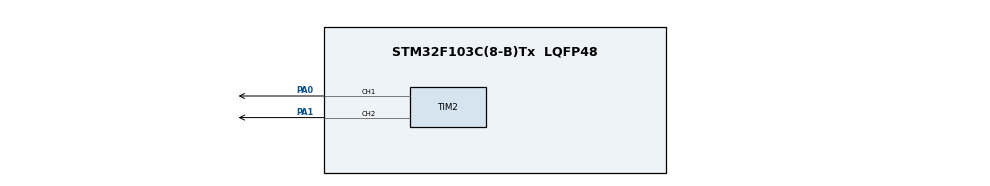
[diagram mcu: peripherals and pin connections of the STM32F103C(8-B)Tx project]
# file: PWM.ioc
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Mcu.Family=STM32F1
Mcu.Name=STM32F103C(8-B)Tx
Mcu.Package=LQFP48
NVIC.PriorityGroup=NVIC_PRIORITYGROUP_4
PA0-WKUP.Signal=S_TIM2_CH1_ETR
PA1.Signal=S_TIM2_CH2
PA13.Mode=Serial_Wire
PA13.Signal=SYS_JTMS-SWDIO
PA14.Mode=Serial_Wire
PA14.Signal=SYS_JTCK-SWCLK
PD0-OSC_IN.Mode=HSE-External-Oscillator
PD0-OSC_IN.Signal=RCC_OSC_IN
PD1-OSC_OUT.Mode=HSE-External-Oscillator
PD1-OSC_OUT.Signal=RCC_OSC_OUT
ProjectManager.HeapSize=0x200
ProjectManager.StackSize=0x400
ProjectManager.TargetToolchain=STM32CubeIDE
RCC.APB1Freq_Value=8000000
RCC.APB2Freq_Value=8000000
SH.S_TIM2_CH1_ETR.0=TIM2_CH1,PWM Generation1 CH1
SH.S_TIM2_CH2.0=TIM2_CH2,PWM Generation2 CH2
TIM2.Channel-PWM\ Generation1\ CH1=TIM_CHANNEL_1
TIM2.Channel-PWM\ Generation2\ CH2=TIM_CHANNEL_2
VP_TIM2_VS_ClockSourceINT.Mode=Internal
board=custom

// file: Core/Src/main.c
/* USER CODE BEGIN Header */
/**
  ******************************************************************************
  * @file           : main.c
  * @brief          : Main program body
  ******************************************************************************
  * @attention
  *
  * This software is licensed under terms that can be found in the LICENSE file
  * in the root directory of this software component.
  *
  ******************************************************************************
  */
/* USER CODE END Header */
#include "main.h"

/* USER CODE BEGIN PD */
#define MAX_DUTY_CYCLE 1000
#define STEP_DUTY_CYCLE 50
#define DELAY_MS 10
/* USER CODE END PD */

TIM_HandleTypeDef htim2;

void SystemClock_Config(void);
static void MX_GPIO_Init(void);
static void MX_TIM2_Init(void);
/* USER CODE BEGIN PFP */
void Set_PWM_DutyCycle(TIM_HandleTypeDef *htim, uint32_t Channel, uint16_t duty_cycle);
/* USER CODE END PFP */

/* USER CODE BEGIN 0 */
void Set_PWM_DutyCycle(TIM_HandleTypeDef *htim, uint32_t Channel, uint16_t duty_cycle) {
    if (duty_cycle <= MAX_DUTY_CYCLE) {
        __HAL_TIM_SET_COMPARE(htim, Channel, duty_cycle);
    }
}

void PWM_Mode() {
    HAL_TIM_PWM_Start(&htim2, TIM_CHANNEL_1);
    HAL_TIM_PWM_Start(&htim2, TIM_CHANNEL_2);

    // Tăng độ rộng xung trên cả hai kênh
    for (uint16_t duty_cycle = 0; duty_cycle <= MAX_DUTY_CYCLE; duty_cycle += STEP_DUTY_CYCLE) {
        Set_PWM_DutyCycle(&htim2, TIM_CHANNEL_1, duty_cycle);
        Set_PWM_DutyCycle(&htim2, TIM_CHANNEL_2, duty_cycle);
        HAL_Delay(DELAY_MS);
    }

    // Giảm độ rộng xung trên cả hai kênh
    for (uint16_t duty_cycle = MAX_DUTY_CYCLE; duty_cycle > 0; duty_cycle -= STEP_DUTY_CYCLE) {
        Set_PWM_DutyCycle(&htim2, TIM_CHANNEL_1, duty_cycle);
        Set_PWM_DutyCycle(&htim2, TIM_CHANNEL_2, duty_cycle);
        HAL_Delay(DELAY_MS);
    }

    HAL_TIM_PWM_Stop(&htim2, TIM_CHANNEL_1);
    HAL_TIM_PWM_Stop(&htim2, TIM_CHANNEL_2);
}
/* USER CODE END 0 */

int main(void)
{

  /* MCU Configuration--------------------------------------------------------*/

  /* Reset of all peripherals, Initializes the Flash interface and the Systick. */
  HAL_Init();

  /* Configure the system clock */
  SystemClock_Config();

  /* Initialize all configured peripherals */
  MX_GPIO_Init();
  MX_TIM2_Init();

  /* Infinite loop */
  /* USER CODE BEGIN WHILE */
  while (1) {
      PWM_Mode();
  }
  /* USER CODE END WHILE */
}

void SystemClock_Config(void)
{
  RCC_OscInitTypeDef RCC_OscInitStruct = {0};
  RCC_ClkInitTypeDef RCC_ClkInitStruct = {0};

  RCC_OscInitStruct.OscillatorType = RCC_OSCILLATORTYPE_HSI;
  RCC_OscInitStruct.HSIState = RCC_HSI_ON;
  RCC_OscInitStruct.HSICalibrationValue = RCC_HSICALIBRATION_DEFAULT;
  RCC_OscInitStruct.PLL.PLLState = RCC_PLL_NONE;
  if (HAL_RCC_OscConfig(&RCC_OscInitStruct) != HAL_OK) {
    Error_Handler();
  }

  RCC_ClkInitStruct.ClockType = RCC_CLOCKTYPE_HCLK | RCC_CLOCKTYPE_SYSCLK
                              | RCC_CLOCKTYPE_PCLK1 | RCC_CLOCKTYPE_PCLK2;
  RCC_ClkInitStruct.SYSCLKSource = RCC_SYSCLKSOURCE_HSI;
  RCC_ClkInitStruct.AHBCLKDivider = RCC_SYSCLK_DIV1;
  RCC_ClkInitStruct.APB1CLKDivider = RCC_HCLK_DIV1;
  RCC_ClkInitStruct.APB2CLKDivider = RCC_HCLK_DIV1;

  if (HAL_RCC_ClockConfig(&RCC_ClkInitStruct, FLASH_LATENCY_0) != HAL_OK) {
    Error_Handler();
  }
}

static void MX_TIM2_Init(void)
{
  TIM_ClockConfigTypeDef sClockSourceConfig = {0};
  TIM_MasterConfigTypeDef sMasterConfig = {0};
  TIM_OC_InitTypeDef sConfigOC = {0};

  htim2.Instance = TIM2;
  htim2.Init.Prescaler = 79;
  htim2.Init.CounterMode = TIM_COUNTERMODE_UP;
  htim2.Init.Period = MAX_DUTY_CYCLE;
  htim2.Init.ClockDivision = TIM_CLOCKDIVISION_DIV1;
  htim2.Init.AutoReloadPreload = TIM_AUTORELOAD_PRELOAD_DISABLE;

  if (HAL_TIM_Base_Init(&htim2) != HAL_OK) {
    Error_Handler();
  }

  sClockSourceConfig.ClockSource = TIM_CLOCKSOURCE_INTERNAL;
  if (HAL_TIM_ConfigClockSource(&htim2, &sClockSourceConfig) != HAL_OK) {
    Error_Handler();
  }
  if (HAL_TIM_PWM_Init(&htim2) != HAL_OK) {
    Error_Handler();
  }

  sMasterConfig.MasterOutputTrigger = TIM_TRGO_RESET;
  sMasterConfig.MasterSlaveMode = TIM_MASTERSLAVEMODE_DISABLE;
  if (HAL_TIMEx_MasterConfigSynchronization(&htim2, &sMasterConfig) != HAL_OK) {
    Error_Handler();
  }

  sConfigOC.OCMode = TIM_OCMODE_PWM1;
  sConfigOC.Pulse = 0;
  sConfigOC.OCPolarity = TIM_OCPOLARITY_HIGH;
  sConfigOC.OCFastMode = TIM_OCFAST_DISABLE;

  if (HAL_TIM_PWM_ConfigChannel(&htim2, &sConfigOC, TIM_CHANNEL_1) != HAL_OK) {
    Error_Handler();
  }
  if (HAL_TIM_PWM_ConfigChannel(&htim2, &sConfigOC, TIM_CHANNEL_2) != HAL_OK) {
    Error_Handler();
  }

  HAL_TIM_MspPostInit(&htim2);
}

static void MX_GPIO_Init(void)
{
  __HAL_RCC_GPIOD_CLK_ENABLE();
  __HAL_RCC_GPIOA_CLK_ENABLE();
}

void Error_Handler(void)
{
  __disable_irq();
  while (1) {
  }
}
